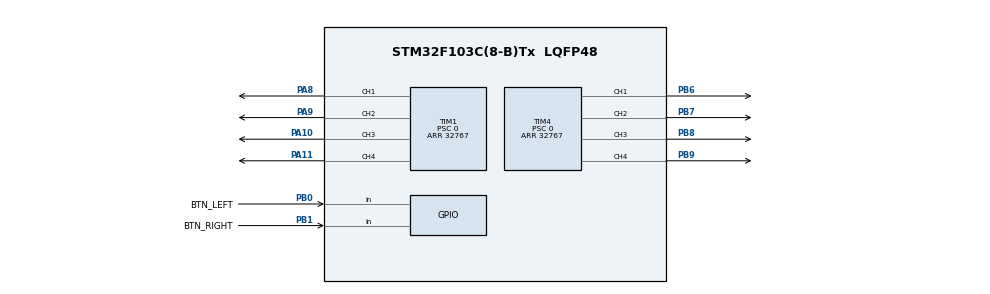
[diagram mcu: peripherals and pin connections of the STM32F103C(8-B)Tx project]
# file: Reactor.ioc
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Mcu.Family=STM32F1
Mcu.Name=STM32F103C(8-B)Tx
Mcu.Package=LQFP48
NVIC.PriorityGroup=NVIC_PRIORITYGROUP_4
NVIC.TIM2_IRQn=true\:0\:0\:false\:false\:true\:true\:true
PA10.Signal=S_TIM1_CH3
PA11.Signal=S_TIM1_CH4
PA13.Mode=Serial_Wire
PA13.Signal=SYS_JTMS-SWDIO
PA14.Mode=Serial_Wire
PA14.Signal=SYS_JTCK-SWCLK
PA8.Signal=S_TIM1_CH1
PA9.Signal=S_TIM1_CH2
PB0.GPIO_Label=BTN_LEFT
PB0.GPIO_PuPd=GPIO_PULLUP
PB0.Signal=GPIO_Input
PB1.GPIO_Label=BTN_RIGHT
PB1.GPIO_PuPd=GPIO_PULLUP
PB1.Signal=GPIO_Input
PB6.Signal=S_TIM4_CH1
PB7.Signal=S_TIM4_CH2
PB8.Signal=S_TIM4_CH3
PB9.Signal=S_TIM4_CH4
PD0-OSC_IN.Mode=HSE-External-Oscillator
PD0-OSC_IN.Signal=RCC_OSC_IN
PD1-OSC_OUT.Mode=HSE-External-Oscillator
PD1-OSC_OUT.Signal=RCC_OSC_OUT
ProjectManager.HeapSize=0x200
ProjectManager.StackSize=0x100
ProjectManager.TargetToolchain=MDK-ARM V5.27
RCC.APB1Freq_Value=8000000
RCC.APB2Freq_Value=8000000
SH.S_TIM1_CH1.0=TIM1_CH1,PWM Generation1 CH1
SH.S_TIM1_CH2.0=TIM1_CH2,PWM Generation2 CH2
SH.S_TIM1_CH3.0=TIM1_CH3,PWM Generation3 CH3
SH.S_TIM1_CH4.0=TIM1_CH4,PWM Generation4 CH4
SH.S_TIM4_CH1.0=TIM4_CH1,PWM Generation1 CH1
SH.S_TIM4_CH2.0=TIM4_CH2,PWM Generation2 CH2
SH.S_TIM4_CH3.0=TIM4_CH3,PWM Generation3 CH3
SH.S_TIM4_CH4.0=TIM4_CH4,PWM Generation4 CH4
TIM1.Channel-PWM\ Generation1\ CH1=TIM_CHANNEL_1
TIM1.Channel-PWM\ Generation2\ CH2=TIM_CHANNEL_2
TIM1.Channel-PWM\ Generation3\ CH3=TIM_CHANNEL_3
TIM1.Channel-PWM\ Generation4\ CH4=TIM_CHANNEL_4
TIM1.Period=32767
TIM1.Prescaler=0
TIM1.Pulse-PWM\ Generation1\ CH1=32767
TIM1.Pulse-PWM\ Generation2\ CH2=32767
TIM1.Pulse-PWM\ Generation3\ CH3=32767
TIM1.Pulse-PWM\ Generation4\ CH4=32767
TIM2.AutoReloadPreload=TIM_AUTORELOAD_PRELOAD_ENABLE
TIM2.Period=9
TIM2.Prescaler=71
TIM4.Channel-PWM\ Generation1\ CH1=TIM_CHANNEL_1
TIM4.Channel-PWM\ Generation2\ CH2=TIM_CHANNEL_2
TIM4.Channel-PWM\ Generation3\ CH3=TIM_CHANNEL_3
TIM4.Channel-PWM\ Generation4\ CH4=TIM_CHANNEL_4
TIM4.Period=32767
TIM4.Prescaler=0
TIM4.Pulse-PWM\ Generation1\ CH1=32767
TIM4.Pulse-PWM\ Generation2\ CH2=32767
TIM4.Pulse-PWM\ Generation3\ CH3=32767
TIM4.Pulse-PWM\ Generation4\ CH4=32767
VP_TIM2_VS_ClockSourceINT.Mode=Internal
board=custom

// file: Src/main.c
/* USER CODE BEGIN Header */
/**
  ******************************************************************************
  * @file           : main.c
  * @brief          : Main program body
  ******************************************************************************
  * @attention
  *
  * <h2><center>&copy; Copyright (c) 2020 STMicroelectronics.
  * All rights reserved.</center></h2>
  *
  * This software component is licensed by ST under BSD 3-Clause license,
  * the "License"; You may not use this file except in compliance with the
  * License. You may obtain a copy of the License at:
  *                        opensource.org/licenses/BSD-3-Clause
  *
  ******************************************************************************
  */
/* USER CODE END Header */

#include "main.h"

TIM_HandleTypeDef htim1;
TIM_HandleTypeDef htim2;
TIM_HandleTypeDef htim4;

void SystemClock_Config(void);
static void MX_GPIO_Init(void);
static void MX_TIM1_Init(void);
static void MX_TIM2_Init(void);
static void MX_TIM4_Init(void);

int main(void)
{

  /* MCU Configuration--------------------------------------------------------*/

  /* Reset of all peripherals, Initializes the Flash interface and the Systick. */
  HAL_Init();

  /* Configure the system clock */
  SystemClock_Config();

  /* Initialize all configured peripherals */
  MX_GPIO_Init();
  MX_TIM1_Init();
  MX_TIM2_Init();
  MX_TIM4_Init();
  /* USER CODE BEGIN 2 */
  begin();
  /* USER CODE END 2 */

  /* Infinite loop */
  while (1)
  {

    /* USER CODE BEGIN 3 */
    loop();
  }
  /* USER CODE END 3 */
}

void SystemClock_Config(void)
{
  RCC_OscInitTypeDef RCC_OscInitStruct = {0};
  RCC_ClkInitTypeDef RCC_ClkInitStruct = {0};

  /** Initializes the CPU, AHB and APB busses clocks
  */
  RCC_OscInitStruct.OscillatorType = RCC_OSCILLATORTYPE_HSI;
  RCC_OscInitStruct.HSIState = RCC_HSI_ON;
  RCC_OscInitStruct.HSICalibrationValue = RCC_HSICALIBRATION_DEFAULT;
  RCC_OscInitStruct.PLL.PLLState = RCC_PLL_NONE;
  if (HAL_RCC_OscConfig(&RCC_OscInitStruct) != HAL_OK)
  {
    Error_Handler();
  }
  /** Initializes the CPU, AHB and APB busses clocks
  */
  RCC_ClkInitStruct.ClockType = RCC_CLOCKTYPE_HCLK|RCC_CLOCKTYPE_SYSCLK
                              |RCC_CLOCKTYPE_PCLK1|RCC_CLOCKTYPE_PCLK2;
  RCC_ClkInitStruct.SYSCLKSource = RCC_SYSCLKSOURCE_HSI;
  RCC_ClkInitStruct.AHBCLKDivider = RCC_SYSCLK_DIV1;
  RCC_ClkInitStruct.APB1CLKDivider = RCC_HCLK_DIV1;
  RCC_ClkInitStruct.APB2CLKDivider = RCC_HCLK_DIV1;

  if (HAL_RCC_ClockConfig(&RCC_ClkInitStruct, FLASH_LATENCY_0) != HAL_OK)
  {
    Error_Handler();
  }
}

static void MX_TIM1_Init(void)
{

  TIM_MasterConfigTypeDef sMasterConfig = {0};
  TIM_OC_InitTypeDef sConfigOC = {0};
  TIM_BreakDeadTimeConfigTypeDef sBreakDeadTimeConfig = {0};

  htim1.Instance = TIM1;
  htim1.Init.Prescaler = 0;
  htim1.Init.CounterMode = TIM_COUNTERMODE_UP;
  htim1.Init.Period = 32767;
  htim1.Init.ClockDivision = TIM_CLOCKDIVISION_DIV1;
  htim1.Init.RepetitionCounter = 0;
  htim1.Init.AutoReloadPreload = TIM_AUTORELOAD_PRELOAD_DISABLE;
  if (HAL_TIM_PWM_Init(&htim1) != HAL_OK)
  {
    Error_Handler();
  }
  sMasterConfig.MasterOutputTrigger = TIM_TRGO_RESET;
  sMasterConfig.MasterSlaveMode = TIM_MASTERSLAVEMODE_DISABLE;
  if (HAL_TIMEx_MasterConfigSynchronization(&htim1, &sMasterConfig) != HAL_OK)
  {
    Error_Handler();
  }
  sConfigOC.OCMode = TIM_OCMODE_PWM1;
  sConfigOC.Pulse = 32767;
  sConfigOC.OCPolarity = TIM_OCPOLARITY_HIGH;
  sConfigOC.OCNPolarity = TIM_OCNPOLARITY_HIGH;
  sConfigOC.OCFastMode = TIM_OCFAST_DISABLE;
  sConfigOC.OCIdleState = TIM_OCIDLESTATE_RESET;
  sConfigOC.OCNIdleState = TIM_OCNIDLESTATE_RESET;
  if (HAL_TIM_PWM_ConfigChannel(&htim1, &sConfigOC, TIM_CHANNEL_1) != HAL_OK)
  {
    Error_Handler();
  }
  if (HAL_TIM_PWM_ConfigChannel(&htim1, &sConfigOC, TIM_CHANNEL_2) != HAL_OK)
  {
    Error_Handler();
  }
  if (HAL_TIM_PWM_ConfigChannel(&htim1, &sConfigOC, TIM_CHANNEL_3) != HAL_OK)
  {
    Error_Handler();
  }
  if (HAL_TIM_PWM_ConfigChannel(&htim1, &sConfigOC, TIM_CHANNEL_4) != HAL_OK)
  {
    Error_Handler();
  }
  sBreakDeadTimeConfig.OffStateRunMode = TIM_OSSR_DISABLE;
  sBreakDeadTimeConfig.OffStateIDLEMode = TIM_OSSI_DISABLE;
  sBreakDeadTimeConfig.LockLevel = TIM_LOCKLEVEL_OFF;
  sBreakDeadTimeConfig.DeadTime = 0;
  sBreakDeadTimeConfig.BreakState = TIM_BREAK_DISABLE;
  sBreakDeadTimeConfig.BreakPolarity = TIM_BREAKPOLARITY_HIGH;
  sBreakDeadTimeConfig.AutomaticOutput = TIM_AUTOMATICOUTPUT_DISABLE;
  if (HAL_TIMEx_ConfigBreakDeadTime(&htim1, &sBreakDeadTimeConfig) != HAL_OK)
  {
    Error_Handler();
  }
  HAL_TIM_MspPostInit(&htim1);

}

static void MX_TIM2_Init(void)
{

  TIM_ClockConfigTypeDef sClockSourceConfig = {0};
  TIM_MasterConfigTypeDef sMasterConfig = {0};

  htim2.Instance = TIM2;
  htim2.Init.Prescaler = 71;
  htim2.Init.CounterMode = TIM_COUNTERMODE_UP;
  htim2.Init.Period = 9;
  htim2.Init.ClockDivision = TIM_CLOCKDIVISION_DIV1;
  htim2.Init.AutoReloadPreload = TIM_AUTORELOAD_PRELOAD_ENABLE;
  if (HAL_TIM_Base_Init(&htim2) != HAL_OK)
  {
    Error_Handler();
  }
  sClockSourceConfig.ClockSource = TIM_CLOCKSOURCE_INTERNAL;
  if (HAL_TIM_ConfigClockSource(&htim2, &sClockSourceConfig) != HAL_OK)
  {
    Error_Handler();
  }
  sMasterConfig.MasterOutputTrigger = TIM_TRGO_RESET;
  sMasterConfig.MasterSlaveMode = TIM_MASTERSLAVEMODE_DISABLE;
  if (HAL_TIMEx_MasterConfigSynchronization(&htim2, &sMasterConfig) != HAL_OK)
  {
    Error_Handler();
  }

}

static void MX_TIM4_Init(void)
{

  TIM_MasterConfigTypeDef sMasterConfig = {0};
  TIM_OC_InitTypeDef sConfigOC = {0};

  htim4.Instance = TIM4;
  htim4.Init.Prescaler = 0;
  htim4.Init.CounterMode = TIM_COUNTERMODE_UP;
  htim4.Init.Period = 32767;
  htim4.Init.ClockDivision = TIM_CLOCKDIVISION_DIV1;
  htim4.Init.AutoReloadPreload = TIM_AUTORELOAD_PRELOAD_DISABLE;
  if (HAL_TIM_PWM_Init(&htim4) != HAL_OK)
  {
    Error_Handler();
  }
  sMasterConfig.MasterOutputTrigger = TIM_TRGO_RESET;
  sMasterConfig.MasterSlaveMode = TIM_MASTERSLAVEMODE_DISABLE;
  if (HAL_TIMEx_MasterConfigSynchronization(&htim4, &sMasterConfig) != HAL_OK)
  {
    Error_Handler();
  }
  sConfigOC.OCMode = TIM_OCMODE_PWM1;
  sConfigOC.Pulse = 32767;
  sConfigOC.OCPolarity = TIM_OCPOLARITY_HIGH;
  sConfigOC.OCFastMode = TIM_OCFAST_DISABLE;
  if (HAL_TIM_PWM_ConfigChannel(&htim4, &sConfigOC, TIM_CHANNEL_1) != HAL_OK)
  {
    Error_Handler();
  }
  if (HAL_TIM_PWM_ConfigChannel(&htim4, &sConfigOC, TIM_CHANNEL_2) != HAL_OK)
  {
    Error_Handler();
  }
  if (HAL_TIM_PWM_ConfigChannel(&htim4, &sConfigOC, TIM_CHANNEL_3) != HAL_OK)
  {
    Error_Handler();
  }
  if (HAL_TIM_PWM_ConfigChannel(&htim4, &sConfigOC, TIM_CHANNEL_4) != HAL_OK)
  {
    Error_Handler();
  }
  HAL_TIM_MspPostInit(&htim4);

}

static void MX_GPIO_Init(void)
{
  GPIO_InitTypeDef GPIO_InitStruct = {0};

  /* GPIO Ports Clock Enable */
  __HAL_RCC_GPIOD_CLK_ENABLE();
  __HAL_RCC_GPIOB_CLK_ENABLE();
  __HAL_RCC_GPIOA_CLK_ENABLE();

  /*Configure GPIO pins : BTN_LEFT_Pin BTN_RIGHT_Pin */
  GPIO_InitStruct.Pin = BTN_LEFT_Pin|BTN_RIGHT_Pin;
  GPIO_InitStruct.Mode = GPIO_MODE_INPUT;
  GPIO_InitStruct.Pull = GPIO_PULLUP;
  HAL_GPIO_Init(GPIOB, &GPIO_InitStruct);

}

void Error_Handler(void)
{
}

/************************ (C) COPYRIGHT STMicroelectronics *****END OF FILE****/
